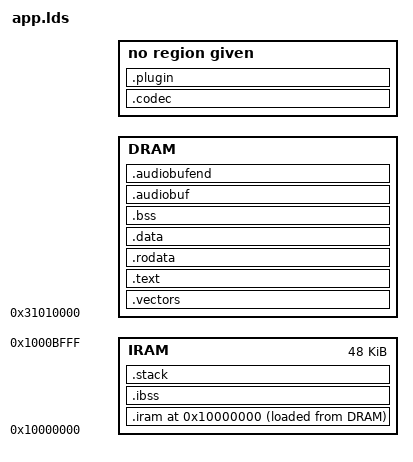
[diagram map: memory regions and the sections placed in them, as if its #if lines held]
#include "config.h"

ENTRY(start)

OUTPUT_FORMAT(elf32-m68k)
INPUT(target/coldfire/crt0.o)

#define PLUGINSIZE PLUGIN_BUFFER_SIZE
#define CODECSIZE CODEC_SIZE

#ifdef DEBUG
#define STUBOFFSET 0x10000
#else
#define STUBOFFSET 0
#endif

#define DRAMSIZE (MEMORYSIZE * 0x100000) - PLUGINSIZE - STUBOFFSET - CODECSIZE

#define DRAMORIG 0x31000000 + STUBOFFSET
#define IRAMORIG 0x10000000
#ifdef IAUDIO_M3
#define IRAMSIZE 0xc000
#else
#define IRAMSIZE 0x10000
#endif

/* End of the audio buffer, where the codec buffer starts */
#define ENDAUDIOADDR  (DRAMORIG + DRAMSIZE)

/* Where the codec buffer ends, and the plugin buffer starts */
#define ENDADDR (ENDAUDIOADDR + CODECSIZE)

MEMORY
{
    DRAM : ORIGIN = DRAMORIG, LENGTH = DRAMSIZE
    IRAM : ORIGIN = IRAMORIG, LENGTH = IRAMSIZE
}

SECTIONS
{
    .vectors :
    {
        loadaddress = .;
        _loadaddress = .;
        KEEP(*(.resetvectors));
        *(.resetvectors);
        KEEP(*(.vectors));
        *(.vectors);
    } > DRAM

    .text :
    {
        . = ALIGN(0x200);
        *(.init.text)
        *(.text*)
        . = ALIGN(0x4);
    } > DRAM

    .rodata :
    {
        *(.rodata)  /* problems without this, dunno why */
        *(.rodata*)
        *(.rodata.str1.1)
        *(.rodata.str1.4)
        . = ALIGN(0x4);

        /* Pseudo-allocate the copies of the data sections */
        _datacopy = .;
    } > DRAM

    /* TRICK ALERT! For RAM execution, we put the .data section at the
       same load address as the copy. Thus, we don't waste extra RAM
       when we don't actually need the copy.  */
    .data : AT ( _datacopy )
    {
        _datastart = .;
        *(.data*)
        . = ALIGN(0x4);
        _dataend  = .;
    } > DRAM

    /DISCARD/ :
    {
        *(.eh_frame)
    }

    .iram IRAMORIG :
    {
        _iramstart = .;
        *(.icode)
        *(.irodata)
        *(.idata)
        _iramend = .;
    } > IRAM AT> DRAM

    _iramcopy = LOADADDR(.iram);

    .ibss (NOLOAD) :
    {
        _iedata = .;
        *(.ibss)
        . = ALIGN(0x4);
        _iend = .;
    } > IRAM

    .stack :
    {
       *(.stack)
       stackbegin = .;
       . += 0x2000;
       stackend = .;
    } > IRAM

    .bss ADDR(.data) + SIZEOF(.data) + SIZEOF(.iram):
    {
       _edata = .;
        *(.bss*)
        *(COMMON)
        . = ALIGN(0x4);
       _end = .;
    } > DRAM

    .audiobuf ALIGN(4) :
    {
        _audiobuffer = .;
        audiobuffer = .;
    } > DRAM

    .audiobufend ENDAUDIOADDR:
    {
        audiobufend = .;
        _audiobufend = .;
    } > DRAM

    .codec ENDAUDIOADDR:
    {
        codecbuf = .;
        _codecbuf = .;
    }

    .plugin ENDADDR:
    {
        _pluginbuf = .;
        pluginbuf = .;
    }
}

